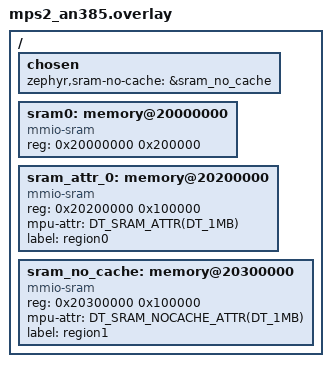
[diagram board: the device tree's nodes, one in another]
/*
 * Copyright (c) 2021 Carlo Caione <ccaione@baylibre.com>
 *
 * SPDX-License-Identifier: Apache-2.0
 */

#include "dt_mpu_attr.h"

/ {
	/delete-node/ memory@20000000;

	chosen {
		zephyr,sram-no-cache = &sram_no_cache;
	};

	sram0: memory@20000000 {
		compatible = "mmio-sram";
		reg = <0x20000000 0x200000>;
	};

	sram_attr_0: memory@20200000 {
		compatible = "mmio-sram";
		reg = <0x20200000 0x100000>;
		mpu-attr = <DT_SRAM_ATTR(DT_1MB)>;
		label = "region0";
	};

	sram_no_cache: memory@20300000 {
		compatible = "mmio-sram";
		reg = <0x20300000 0x100000>;
		mpu-attr = <DT_SRAM_NOCACHE_ATTR(DT_1MB)>;
		label = "region1";
	};
};
